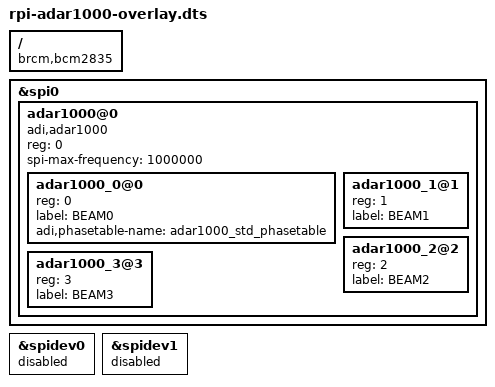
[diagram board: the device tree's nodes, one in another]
// SPDX-License-Identifier: GPL-2.0
/dts-v1/;
/plugin/;

/ {
	compatible = "brcm,bcm2835", "brcm,bcm2708", "brcm,bcm2709";
};

&spi0 {
	#address-cells = <1>;
	#size-cells = <0>;
	status = "okay";

	adar1000@0 {
		compatible = "adi,adar1000";
		reg = <0>;
		spi-max-frequency = <1000000>;

		#address-cells = <1>;
		#size-cells = <0>;

		adar1000_0@0 {
			reg = <0>;
			label = "BEAM0";
			adi,phasetable-name = "adar1000_std_phasetable";
		};
		adar1000_1@1 {
			reg = <1>;
			label = "BEAM1";
		};
		adar1000_2@2 {
			reg = <2>;
			label = "BEAM2";
		};
		adar1000_3@3 {
			reg = <3>;
			label = "BEAM3";
		};
	};
};

&spidev0 {
	status = "disabled";
};

&spidev1 {
	status = "disabled";
};
